# SF32LB57x register map
File version: 1.0
CPU: CM33 r0p1, little endian, MPU, FPU, 3 interrupt priority bits
Registers are 32-bit, read-write, reset 0x0 unless marked. A register's access mark holds for its fields unless they carry their own. Offsets are from the block's base; [hi:lo] are bit positions.

## EZIP1
Base 0x50006000
0x00 EZIP_CTRL — ezip/aezip_frame decoder ctrl
  [0] EZIP_CTRL — 1:start or run 0:stop or end
0x04 SRC_ADDR — ezip decoder source address
0x08 DST_ADDR — ezip decoder destination address
  [31:0] DST_ADDR — ezip decoder destination address(ahb_out mode)
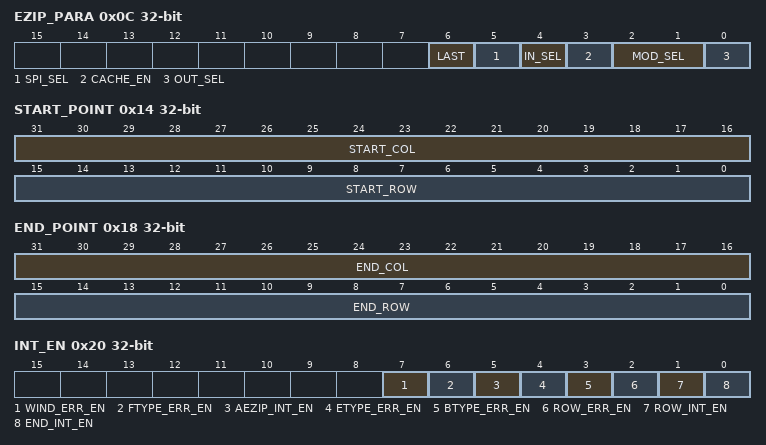
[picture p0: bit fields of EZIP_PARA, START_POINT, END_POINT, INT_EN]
0x0C EZIP_PARA — ezip decoder parameter
  [6] LAST — gzip last block flag 0:not last block data 1:last block data,when the decompressing of this block data is completed,the entrie data is decompressed
  [5] SPI_SEL — 0:QSPI4 1:QSPI3
  [4] IN_SEL — don't support ezip type2 ype4. 0:ahb 1:fifo
  [3] CACHE_EN — no used
  [2:1] MOD_SEL — 0:ezip or aezip 1:gzip 2:Lz4
  [0] OUT_SEL — only used in ezip decoder mode. must select ahb in gzip/lz4 decoder mode. 0:epic 1:ahb
0x10 CACHE_CLR — ezip index cache clear
  [0] CACHE_CLR — no used
0x14 START_POINT — ezip decoder start point
  [31:16] START_COL — ezip start col,count from 0
  [15:0] START_ROW — ezip start row,count from 0
0x18 END_POINT — ezip decoder end point
  [31:16] END_COL — ezip end col
  [15:0] END_ROW — ezip end row
0x1C ROW_SIGN — ezip decoder row sign
  [15:0] ROW_SIGN — arrived row sign,ezip can generate a interrupt
0x20 INT_EN — ezip decoder _int_en
  [7] WIND_ERR_EN
  [6] FTYPE_ERR_EN — ezip_ftype_err_en
  [5] AEZIP_INT_EN — aezip_frame_int_en
  [4] ETYPE_ERR_EN — ezip_type_err_en
  [3] BTYPE_ERR_EN
  [2] ROW_ERR_EN
  [1] ROW_INT_EN
  [0] END_INT_EN — ezip_end _int_en
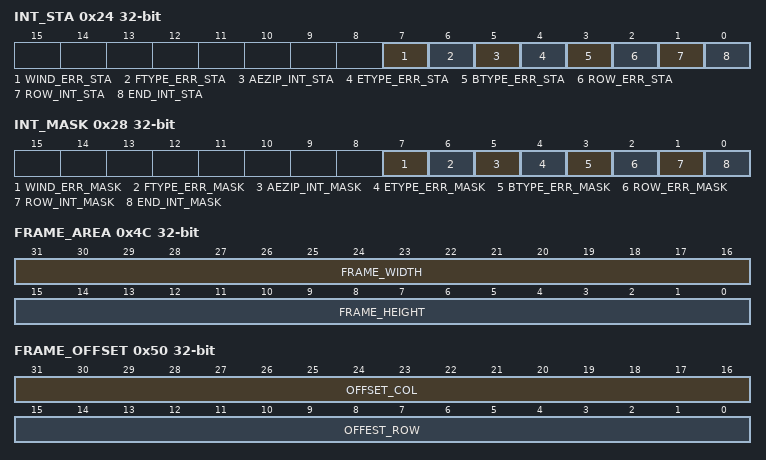
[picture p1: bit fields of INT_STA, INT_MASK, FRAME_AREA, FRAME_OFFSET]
0x24 INT_STA — ezip decoder _int_sta
  [7] WIND_ERR_STA
  [6] FTYPE_ERR_STA — ezip_ftype_err_sta
  [5] AEZIP_INT_STA — aezip_end_int_sta
  [4] ETYPE_ERR_STA — ezip_type_err_sta
  [3] BTYPE_ERR_STA
  [2] ROW_ERR_STA — overflow height sta
  [1] ROW_INT_STA — arrive row sign sta
  [0] END_INT_STA — ezip_end _int_sta/aezip_frame_int_sta
0x28 INT_MASK — ezip decoder int mask state
  [7] WIND_ERR_MASK — wind_err_mask sta
  [6] FTYPE_ERR_MASK — ezip_ftype_err_mask sta
  [5] AEZIP_INT_MASK — aezip_end_int_mask sta
  [4] ETYPE_ERR_MASK — ezip_type_err_mask sta
  [3] BTYPE_ERR_MASK — btype_err_mask sta
  [2] ROW_ERR_MASK — overflow height mask sta
  [1] ROW_INT_MASK — arrive row sign mask sta
  [0] END_INT_MASK — ezip_end _int mask sta/aezip_frame_int_mask_Sta
0x2C GZIP_CTRL — ezip decoder gzip CTRL
  [0] GZIP_CTRL
0x30 SRC_LEN — ezip source data length
  [31:0] SRC_LEN — source data byte length in source data fifo mode and gzip mode
0x34 AEZIP_CTRL
  [0] AEZIP_CTRL
0x38 FRAME_START — Aezip start number of frames
  [31:0] FRAME_START — start number of frames,count from 1
0x3C PLAY_START — Aezip start number of play
  [31:0] PLAY_START — start number of times to loop this AEZIP,,count from 1
0x40 FRAME_NUM — Aezip number of frames
  [31:0] FRAME_NUM — number of frames
0x44 PLAY_NUM — Aezip number of times to loop this AEZIP
  [31:0] PLAY_NUM — number of times to loop this AEZIP,0 indicates infinite looping
0x48 SEQ_NUM — Aezip sequence number
  [31:0] SEQ_NUM — sequence number of the animation chunk,starting from 0
0x4C FRAME_AREA — Aezip frame area
  [31:16] FRAME_WIDTH — AEZIP frame width
  [15:0] FRAME_HEIGHT — AEZIP frame height
0x50 FRAME_OFFSET — Aezip frame area
  [31:16] OFFSET_COL — AEZIP frame offset col
  [15:0] OFFEST_ROW — AEZIP frame offset row
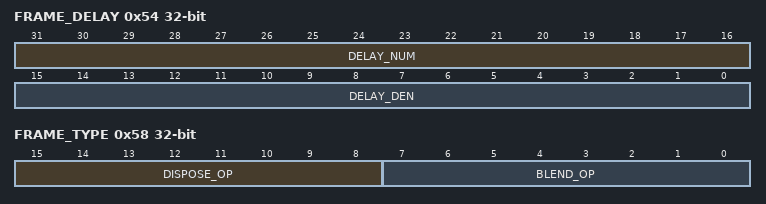
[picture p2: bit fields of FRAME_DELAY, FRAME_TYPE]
0x54 FRAME_DELAY — Aezip frame delay
  [31:16] DELAY_NUM — AEZIP frame delay fraction numerator
  [15:0] DELAY_DEN — AEZIP frame delay fraction denominator
0x58 FRAME_TYPE
  [15:8] DISPOSE_OP — AEZIP type of frame area disposal to be done after rendering this frame
  [7:0] BLEND_OP — AEZIP type of frame area renndering for this frame
0x5C FRAME_SIZE — Aezip frame size
0x60 GREY_PARA
  [23:0] GREY_PARA — fill color parameter, when send grey data to epic . [23:16]-R,[15:8]-G,[7:0]-B
0x64 DB_SEL — ezip decoder debug sel
  [15:0] DB_SEL — bit[15] 0:line_first 1:out_buf_en[1] bit[14] 0:rd_head3 1:out_buf_en[0] bit[13] 0:rd_head2 1:inbuf_empty bit[12] 0:rd_heas1 1:inbuf_half_empty bit[11] 0:blk_restart 1: inbuf_full bit[10] 0:ezip_buf_end 1:ezip_pixel_end bit[9] 0:ezip_buf_full 1:0 bit[8] 0:ezip_buf_empty 1:0 bit[7] 0:dec_buf_empty 1:0 bit[6] 0:dec_buf_full 1:para_ok bit[5] 0:dec_on 1:ezip_fuf_push bit[4] 0:ind3_on 1:copy_on bit[3] 0:ind2_on 1:bypass_on bit[2] 0:ind1_on 1:blk_clr bit[1] 0:ezip_on 1:para_val bit[0] 0:ezip_int 1:para_req
0x68 DB_DATA0 — ezip decoder debug data0
  [31:0] DB_DATA0 — bit[31:24] bit_depth bit[23:16] color_type bit[15:0] block number
0x6C DB_DATA1 — ezip decoder debug data1
  [31:0] DB_DATA1 — bit[31:16] width bit[15:0] height
0x70 DB_DATA2 — ezip decoder debug data2
  [31:0] DB_DATA2 — bit[31:0] total_len
0x74 DB_DATA3 — ezip decoder debug data3
  [31:0] DB_DATA3 — bit[31:28] filter_type bit[27:24] ezip_type bit[23:20] bfinal bit[19:16] btype bit[11:8] ahb_state bit[7:4] ctrl_state bir[3:0] build_stste
0x78 DB_DATA4 — ezip decoder debug data4
  [31:0] DB_DATA4 — bit[31:16]: wind_size bit[11]:jpegd_mem_busy bit[10]:jpegd_mem_sel bit[9]:ezip_buf_full bit[8]:ezip_buf_empty bit[7]:dec_buf_full bit[6]:dec_buf_empty bit[5]:bypass_on bit[4]:dec_on bit[3]:ind3_on bit[2]:ind2_on bit[1]:ind1_on bit[0]:ezip_on
0x7C DB_DATA5 — ezip decoder debug data5
  [31:0] DB_DATA5 — bit[31:16] width_cnt_cur bit[15:0] height_cnt_cur
0x80 DB_DATA6 — ezip decoder debug data6
  [31:0] DB_DATA6 — seq_num
0x84 DB_DATA7 — ezip decoder debug data7
  [31:0] DB_DATA7 — bit[31:16] frame_width_cur bit[15:0] frame_height_cur
0x88 DB_DATA8 — ezip decoder debug data8
  [31:0] DB_DATA8 — bit[31:16 ]frame_offsetx_cur bit[15:0] frame_offsety_cur
0x8C DB_DATA9 — ezip decoder debug data9
  [31:0] DB_DATA9 — bit[31:16 ]delay_num_cur bit[15:0] delay_den_cur
0x90 DB_DATA10 — ezip decoder debug data10
  [31:0] DB_DATA10 — bit[15:8 dispos_op_cur bit[7:0] blend_op_cur
0x94 DB_DATA11 — ezip decoder debug data11
  [31:0] DB_DATA11 — frame_cont_cur
0x98 DB_DATA12 — ezip decoder debug data12
  [31:0] DB_DATA12 — paly_cont_cur
0x9C DB_DATA13 — ezip decoder debug data13
  [31:0] DB_DATA13 — frame_size_cur
